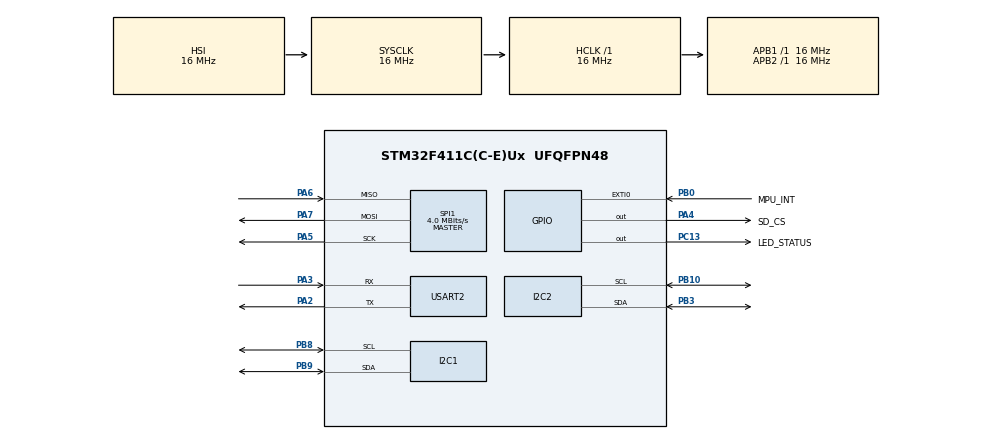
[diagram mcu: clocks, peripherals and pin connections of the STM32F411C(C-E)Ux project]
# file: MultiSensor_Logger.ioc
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Dma.Request0=USART2_TX
Dma.USART2_TX.0.Direction=DMA_MEMORY_TO_PERIPH
Dma.USART2_TX.0.FIFOMode=DMA_FIFOMODE_DISABLE
Dma.USART2_TX.0.Instance=DMA1_Stream6
Dma.USART2_TX.0.MemDataAlignment=DMA_MDATAALIGN_BYTE
Dma.USART2_TX.0.MemInc=DMA_MINC_ENABLE
Dma.USART2_TX.0.Mode=DMA_NORMAL
Dma.USART2_TX.0.PeriphDataAlignment=DMA_PDATAALIGN_BYTE
Dma.USART2_TX.0.PeriphInc=DMA_PINC_DISABLE
Dma.USART2_TX.0.Priority=DMA_PRIORITY_LOW
FATFS._USE_LFN=3
FREERTOS.Tasks01=defaultTask,24,128,StartDefaultTask,Default,NULL,Dynamic,NULL,NULL
FREERTOS.configCHECK_FOR_STACK_OVERFLOW=2
FREERTOS.configTOTAL_HEAP_SIZE=20480
FREERTOS.configUSE_NEWLIB_REENTRANT=1
I2C1.I2C_Mode=I2C_Fast
IWDG.Prescaler=IWDG_PRESCALER_32
IWDG.Reload=1249
Mcu.Family=STM32F4
Mcu.Name=STM32F411C(C-E)Ux
Mcu.Package=UFQFPN48
NVIC.DMA1_Stream6_IRQn=true\:5\:0\:false\:false\:true\:true\:false\:true\:true
NVIC.PriorityGroup=NVIC_PRIORITYGROUP_4
NVIC.TIM1_TRG_COM_TIM11_IRQn=true\:15\:0\:false\:false\:true\:false\:false\:true\:true
NVIC.TimeBase=TIM1_TRG_COM_TIM11_IRQn
NVIC.TimeBaseIP=TIM11
PA2.Mode=Asynchronous
PA2.Signal=USART2_TX
PA3.Mode=Asynchronous
PA3.Signal=USART2_RX
PA4.GPIO_Label=SD_CS
PA4.Signal=GPIO_Output
PA5.Mode=Full_Duplex_Master
PA5.Signal=SPI1_SCK
PA6.Mode=Full_Duplex_Master
PA6.Signal=SPI1_MISO
PA7.Mode=Full_Duplex_Master
PA7.Signal=SPI1_MOSI
PB0.GPIO_Label=MPU_INT
PB0.GPIO_ModeDefaultEXTI=GPIO_MODE_IT_RISING
PB0.Signal=GPXTI0
PB10.Mode=I2C
PB10.Signal=I2C2_SCL
PB3.Mode=I2C
PB3.Signal=I2C2_SDA
PB8.Mode=I2C
PB8.Signal=I2C1_SCL
PB9.Mode=I2C
PB9.Signal=I2C1_SDA
PC13-ANTI_TAMP.GPIO_Label=LED_STATUS
PC13-ANTI_TAMP.Signal=GPIO_Output
PH0\ -\ OSC_IN.Mode=HSE-External-Oscillator
PH0\ -\ OSC_IN.Signal=RCC_OSC_IN
PH1\ -\ OSC_OUT.Mode=HSE-External-Oscillator
PH1\ -\ OSC_OUT.Signal=RCC_OSC_OUT
ProjectManager.HeapSize=0x200
ProjectManager.StackSize=0x400
ProjectManager.TargetToolchain=STM32CubeIDE
RCC.AHBFreq_Value=16000000
RCC.APB1Freq_Value=16000000
RCC.APB2Freq_Value=16000000
RCC.CortexFreq_Value=16000000
RCC.HSE_VALUE=25000000
RCC.HSI_VALUE=16000000
RCC.LSE_VALUE=32768
RCC.SYSCLKFreq_VALUE=16000000
RCC.VCOOutputFreq_Value=192000000
SPI1.BaudRatePrescaler=SPI_BAUDRATEPRESCALER_4
SPI1.CalculateBaudRate=4.0 MBits/s
SPI1.Direction=SPI_DIRECTION_2LINES
SPI1.Mode=SPI_MODE_MASTER
SPI1.VirtualType=VM_MASTER
USART2.VirtualMode=VM_ASYNC
VP_CRC_VS_CRC.Mode=CRC_Activate
VP_FATFS_VS_Generic.Mode=User_defined
VP_FREERTOS_VS_CMSIS_V2.Mode=CMSIS_V2
VP_IWDG_VS_IWDG.Mode=IWDG_Activate
VP_RTC_VS_RTC_Activate.Mode=RTC_Enabled
VP_SYS_VS_tim11.Mode=TIM11
board=custom

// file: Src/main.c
/* USER CODE BEGIN Header */
/**
  ******************************************************************************
  * @file           : main.c
  * @brief          : Main program body
  ******************************************************************************
  * @attention
  *
  * Copyright (c) 2026 STMicroelectronics.
  * All rights reserved.
  *
  * This software is licensed under terms that can be found in the LICENSE file
  * in the root directory of this software component.
  * If no LICENSE file comes with this software, it is provided AS-IS.
  *
  ******************************************************************************
  */
/* USER CODE END Header */
#include "main.h"
#include "cmsis_os.h"
#include "fatfs.h"

/* USER CODE BEGIN Includes */
#include "freertos_tasks.h"
#include "sensor_types.h"
#include "bme280_driver.h"
#include "mpu6050_driver.h"
/* USER CODE END Includes */

CRC_HandleTypeDef hcrc;

I2C_HandleTypeDef hi2c1;
I2C_HandleTypeDef hi2c2;

IWDG_HandleTypeDef hiwdg;

RTC_HandleTypeDef hrtc;

SPI_HandleTypeDef hspi1;

UART_HandleTypeDef huart2;
DMA_HandleTypeDef hdma_usart2_tx;

/* Definitions for defaultTask */
osThreadId_t defaultTaskHandle;
const osThreadAttr_t defaultTask_attributes = {
  .name = "defaultTask",
  .stack_size = 128 * 4,
  .priority = (osPriority_t) osPriorityNormal,
};

void SystemClock_Config(void);
static void MX_GPIO_Init(void);
static void MX_DMA_Init(void);
static void MX_I2C1_Init(void);
static void MX_USART2_UART_Init(void);
static void MX_I2C2_Init(void);
static void MX_IWDG_Init(void);
static void MX_SPI1_Init(void);
static void MX_RTC_Init(void);
static void MX_CRC_Init(void);
void StartDefaultTask(void *argument);

int main(void)
{

  /* MCU Configuration--------------------------------------------------------*/

  /* Reset of all peripherals, Initializes the Flash interface and the Systick. */
  HAL_Init();

  /* Configure the system clock */
  SystemClock_Config();

  /* Initialize all configured peripherals */
  MX_GPIO_Init();
  MX_DMA_Init();
  MX_I2C1_Init();
  MX_USART2_UART_Init();
  MX_I2C2_Init();
  MX_IWDG_Init();
  MX_SPI1_Init();
  MX_RTC_Init();
  MX_CRC_Init();
  MX_FATFS_Init();
  /* USER CODE BEGIN 2 */
  BME280_Init(&hi2c1);
  MPU6050_Init(&hi2c2);
  RTOS_CreateAll();
  /* USER CODE END 2 */

  /* Init scheduler */
  osKernelInitialize();

  /* Create the thread(s) */
  /* creation of defaultTask */
  defaultTaskHandle = osThreadNew(StartDefaultTask, NULL, &defaultTask_attributes);

  /* Start scheduler */
  osKernelStart();

  /* We should never get here as control is now taken by the scheduler */

  /* Infinite loop */
  while (1)
  {

  }
}

void SystemClock_Config(void)
{
  RCC_OscInitTypeDef RCC_OscInitStruct = {0};
  RCC_ClkInitTypeDef RCC_ClkInitStruct = {0};

  /** Configure the main internal regulator output voltage
  */
  __HAL_RCC_PWR_CLK_ENABLE();
  __HAL_PWR_VOLTAGESCALING_CONFIG(PWR_REGULATOR_VOLTAGE_SCALE1);

  /** Initializes the RCC Oscillators according to the specified parameters
  * in the RCC_OscInitTypeDef structure.
  */
  RCC_OscInitStruct.OscillatorType = RCC_OSCILLATORTYPE_HSI|RCC_OSCILLATORTYPE_LSI;
  RCC_OscInitStruct.HSIState = RCC_HSI_ON;
  RCC_OscInitStruct.HSICalibrationValue = RCC_HSICALIBRATION_DEFAULT;
  RCC_OscInitStruct.LSIState = RCC_LSI_ON;
  RCC_OscInitStruct.PLL.PLLState = RCC_PLL_NONE;
  if (HAL_RCC_OscConfig(&RCC_OscInitStruct) != HAL_OK)
  {
    Error_Handler();
  }

  /** Initializes the CPU, AHB and APB buses clocks
  */
  RCC_ClkInitStruct.ClockType = RCC_CLOCKTYPE_HCLK|RCC_CLOCKTYPE_SYSCLK
                              |RCC_CLOCKTYPE_PCLK1|RCC_CLOCKTYPE_PCLK2;
  RCC_ClkInitStruct.SYSCLKSource = RCC_SYSCLKSOURCE_HSI;
  RCC_ClkInitStruct.AHBCLKDivider = RCC_SYSCLK_DIV1;
  RCC_ClkInitStruct.APB1CLKDivider = RCC_HCLK_DIV1;
  RCC_ClkInitStruct.APB2CLKDivider = RCC_HCLK_DIV1;

  if (HAL_RCC_ClockConfig(&RCC_ClkInitStruct, FLASH_LATENCY_0) != HAL_OK)
  {
    Error_Handler();
  }
}

static void MX_CRC_Init(void)
{
  hcrc.Instance = CRC;
  if (HAL_CRC_Init(&hcrc) != HAL_OK)
  {
    Error_Handler();
  }
}

static void MX_I2C1_Init(void)
{
  hi2c1.Instance = I2C1;
  hi2c1.Init.ClockSpeed = 400000;
  hi2c1.Init.DutyCycle = I2C_DUTYCYCLE_2;
  hi2c1.Init.OwnAddress1 = 0;
  hi2c1.Init.AddressingMode = I2C_ADDRESSINGMODE_7BIT;
  hi2c1.Init.DualAddressMode = I2C_DUALADDRESS_DISABLE;
  hi2c1.Init.OwnAddress2 = 0;
  hi2c1.Init.GeneralCallMode = I2C_GENERALCALL_DISABLE;
  hi2c1.Init.NoStretchMode = I2C_NOSTRETCH_DISABLE;
  if (HAL_I2C_Init(&hi2c1) != HAL_OK)
  {
    Error_Handler();
  }
}

static void MX_I2C2_Init(void)
{
  hi2c2.Instance = I2C2;
  hi2c2.Init.ClockSpeed = 100000;
  hi2c2.Init.DutyCycle = I2C_DUTYCYCLE_2;
  hi2c2.Init.OwnAddress1 = 0;
  hi2c2.Init.AddressingMode = I2C_ADDRESSINGMODE_7BIT;
  hi2c2.Init.DualAddressMode = I2C_DUALADDRESS_DISABLE;
  hi2c2.Init.OwnAddress2 = 0;
  hi2c2.Init.GeneralCallMode = I2C_GENERALCALL_DISABLE;
  hi2c2.Init.NoStretchMode = I2C_NOSTRETCH_DISABLE;
  if (HAL_I2C_Init(&hi2c2) != HAL_OK)
  {
    Error_Handler();
  }
}

static void MX_IWDG_Init(void)
{
  hiwdg.Instance = IWDG;
  hiwdg.Init.Prescaler = IWDG_PRESCALER_32;
  hiwdg.Init.Reload = 1249;
  if (HAL_IWDG_Init(&hiwdg) != HAL_OK)
  {
    Error_Handler();
  }
}

static void MX_RTC_Init(void)
{
  hrtc.Instance = RTC;
  hrtc.Init.HourFormat = RTC_HOURFORMAT_24;
  hrtc.Init.AsynchPrediv = 127;
  hrtc.Init.SynchPrediv = 255;
  hrtc.Init.OutPut = RTC_OUTPUT_DISABLE;
  hrtc.Init.OutPutPolarity = RTC_OUTPUT_POLARITY_HIGH;
  hrtc.Init.OutPutType = RTC_OUTPUT_TYPE_OPENDRAIN;
  if (HAL_RTC_Init(&hrtc) != HAL_OK)
  {
    Error_Handler();
  }
}

static void MX_SPI1_Init(void)
{
  hspi1.Instance = SPI1;
  hspi1.Init.Mode = SPI_MODE_MASTER;
  hspi1.Init.Direction = SPI_DIRECTION_2LINES;
  hspi1.Init.DataSize = SPI_DATASIZE_8BIT;
  hspi1.Init.CLKPolarity = SPI_POLARITY_LOW;
  hspi1.Init.CLKPhase = SPI_PHASE_1EDGE;
  hspi1.Init.NSS = SPI_NSS_SOFT;
  hspi1.Init.BaudRatePrescaler = SPI_BAUDRATEPRESCALER_4;
  hspi1.Init.FirstBit = SPI_FIRSTBIT_MSB;
  hspi1.Init.TIMode = SPI_TIMODE_DISABLE;
  hspi1.Init.CRCCalculation = SPI_CRCCALCULATION_DISABLE;
  hspi1.Init.CRCPolynomial = 10;
  if (HAL_SPI_Init(&hspi1) != HAL_OK)
  {
    Error_Handler();
  }
}

static void MX_USART2_UART_Init(void)
{
  huart2.Instance = USART2;
  huart2.Init.BaudRate = 115200;
  huart2.Init.WordLength = UART_WORDLENGTH_8B;
  huart2.Init.StopBits = UART_STOPBITS_1;
  huart2.Init.Parity = UART_PARITY_NONE;
  huart2.Init.Mode = UART_MODE_TX_RX;
  huart2.Init.HwFlowCtl = UART_HWCONTROL_NONE;
  huart2.Init.OverSampling = UART_OVERSAMPLING_16;
  if (HAL_UART_Init(&huart2) != HAL_OK)
  {
    Error_Handler();
  }
}

static void MX_DMA_Init(void)
{
  /* DMA controller clock enable */
  __HAL_RCC_DMA1_CLK_ENABLE();

  /* DMA interrupt init */
  /* DMA1_Stream6_IRQn interrupt configuration */
  HAL_NVIC_SetPriority(DMA1_Stream6_IRQn, 5, 0);
  HAL_NVIC_EnableIRQ(DMA1_Stream6_IRQn);
}

static void MX_GPIO_Init(void)
{
  GPIO_InitTypeDef GPIO_InitStruct = {0};

  /* GPIO Ports Clock Enable */
  __HAL_RCC_GPIOC_CLK_ENABLE();
  __HAL_RCC_GPIOH_CLK_ENABLE();
  __HAL_RCC_GPIOA_CLK_ENABLE();
  __HAL_RCC_GPIOB_CLK_ENABLE();

  /*Configure GPIO pin Output Level */
  HAL_GPIO_WritePin(LED_STATUS_GPIO_Port, LED_STATUS_Pin, GPIO_PIN_RESET);

  /*Configure GPIO pin Output Level */
  HAL_GPIO_WritePin(SD_CS_GPIO_Port, SD_CS_Pin, GPIO_PIN_RESET);

  /*Configure GPIO pin : LED_STATUS_Pin */
  GPIO_InitStruct.Pin = LED_STATUS_Pin;
  GPIO_InitStruct.Mode = GPIO_MODE_OUTPUT_PP;
  GPIO_InitStruct.Pull = GPIO_NOPULL;
  GPIO_InitStruct.Speed = GPIO_SPEED_FREQ_LOW;
  HAL_GPIO_Init(LED_STATUS_GPIO_Port, &GPIO_InitStruct);

  /*Configure GPIO pin : SD_CS_Pin */
  GPIO_InitStruct.Pin = SD_CS_Pin;
  GPIO_InitStruct.Mode = GPIO_MODE_OUTPUT_PP;
  GPIO_InitStruct.Pull = GPIO_NOPULL;
  GPIO_InitStruct.Speed = GPIO_SPEED_FREQ_LOW;
  HAL_GPIO_Init(SD_CS_GPIO_Port, &GPIO_InitStruct);

  /*Configure GPIO pin : MPU_INT_Pin */
  GPIO_InitStruct.Pin = MPU_INT_Pin;
  GPIO_InitStruct.Mode = GPIO_MODE_IT_RISING;
  GPIO_InitStruct.Pull = GPIO_NOPULL;
  HAL_GPIO_Init(MPU_INT_GPIO_Port, &GPIO_InitStruct);
}

/* USER CODE BEGIN 4 */
/* DMA UART TX complete -> notify UARTTask */
void HAL_UART_TxCpltCallback(UART_HandleTypeDef *huart) {
    if (huart->Instance == USART2) {
        extern void UART_TxDoneCallback(void);
        UART_TxDoneCallback();
    }
}
/* USER CODE END 4 */

void StartDefaultTask(void *argument)
{
  for(;;)
  {
    osDelay(1);
  }
}

void HAL_TIM_PeriodElapsedCallback(TIM_HandleTypeDef *htim)
{
  if (htim->Instance == TIM11)
  {
    HAL_IncTick();
  }
}

void Error_Handler(void)
{
  __disable_irq();
  while (1)
  {
  }
}
